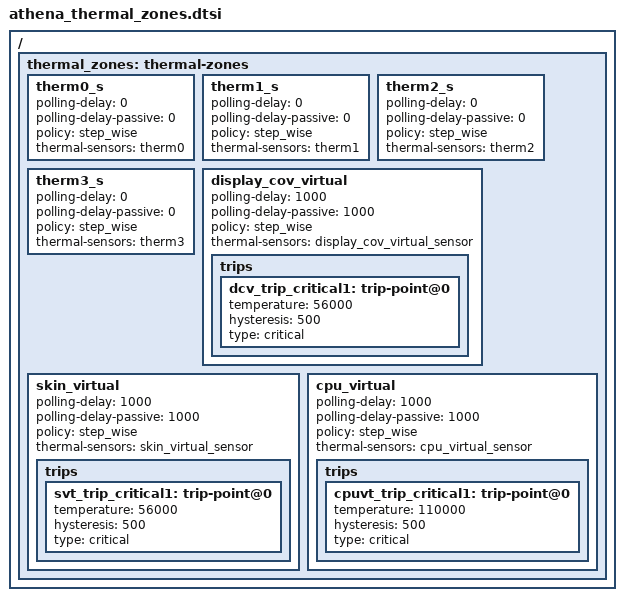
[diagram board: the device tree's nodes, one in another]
/*
 * arch/arm64/boot/dts/mediatek/athena_thermal_zones.dtsi
 *
 * Copyright (C) 2020 Amazon, Inc. All rights reserved.
 *
 * This program is free software; you can redistribute it and/or modify
 * it under the terms of the GNU General Public License as published by
 * the Free Software Foundation; either version 2 of the License, or
 * (at your option) any later version.
 *
 * This program is distributed in the hope that it will be useful, but WITHOUT
 * ANY WARRANTY; without even the implied warranty of MERCHANTABILITY or
 * FITNESS FOR A PARTICULAR PURPOSE.  See the GNU General Public License for
 * more details.
 *
 */

/ {

	thermal_zones: thermal-zones {
		therm0_s {
			polling-delay = <0>;
			polling-delay-passive = <0>;
			policy = "step_wise";
			thermal-sensors = <&therm0>;
		}; /* touch therm */

		therm1_s {
			polling-delay = <0>;
			polling-delay-passive = <0>;
			policy = "step_wise";
			thermal-sensors = <&therm1>;
		};

		therm2_s {
			polling-delay = <0>;
			polling-delay-passive = <0>;
			policy = "step_wise";
			thermal-sensors = <&therm2>;
		};

		therm3_s {
			polling-delay = <0>;
			polling-delay-passive = <0>;
			policy = "step_wise";
			thermal-sensors = <&therm3>;
		};

		display_cov_virtual {
			polling-delay = <1000>;
			polling-delay-passive = <1000>;
			policy = "step_wise";
			thermal-sensors = <&display_cov_virtual_sensor>;

			/* dcv is short for display_cov_virtual */
			trips {
				dcv_trip_critical1: trip-point@0 {
					temperature = <56000>;
					hysteresis = <500>;
					type = "critical";
				};
			};
		};

		skin_virtual {
			polling-delay = <1000>;
			polling-delay-passive = <1000>;
			policy = "step_wise";
			thermal-sensors = <&skin_virtual_sensor>;

			/* svt is short of skin_virtual_thermal */
			trips {
				svt_trip_critical1: trip-point@0 {
					temperature = <56000>;
					hysteresis = <500>;
					type = "critical";
				};
			};
		};

		cpu_virtual: cpu_virtual {
			polling-delay = <1000>;
			polling-delay-passive = <1000>;
			policy = "step_wise";
			thermal-sensors = <&cpu_virtual_sensor>;

			trips {
				cpuvt_trip_critical1: trip-point@0 {
					temperature = <110000>;
					hysteresis = <500>;
					type = "critical";
				};
			};
		};

	 }; /* thermal-zones */
 };
